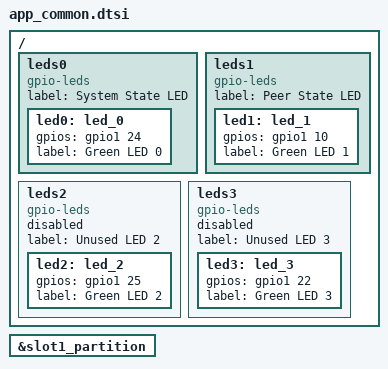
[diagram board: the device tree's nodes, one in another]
/*
 * Copyright (c) 2026 Nordic Semiconductor ASA
 *
 * SPDX-License-Identifier: LicenseRef-Nordic-5-Clause
 */

#include "memory_map.dtsi"

/ {
	/* Redefine leds to fit CAF requirements.
	 * Remove the default leds DTS node.
	 */
	/delete-node/ leds;

	leds0 {
		compatible = "gpio-leds";
		status = "okay";
		label = "System State LED";

		led0: led_0 {
			gpios = <&gpio1 24 GPIO_ACTIVE_HIGH>;
			label = "Green LED 0";
		};
	};

	leds1 {
		compatible = "gpio-leds";
		status = "okay";
		label = "Peer State LED";

		led1: led_1 {
			gpios = <&gpio1 10 GPIO_ACTIVE_HIGH>;
			label = "Green LED 1";
		};
	};

	leds2 {
		compatible = "gpio-leds";
		status = "disabled";
		label = "Unused LED 2";

		led2: led_2 {
			gpios = <&gpio1 25 GPIO_ACTIVE_HIGH>;
			label = "Green LED 2";
		};
	};

	leds3 {
		compatible = "gpio-leds";
		status = "disabled";
		label = "Unused LED 3";

		led3: led_3 {
			gpios = <&gpio1 22 GPIO_ACTIVE_HIGH>;
			label = "Green LED 3";
		};
	};
};

secondary_app_partition: &slot1_partition {};
